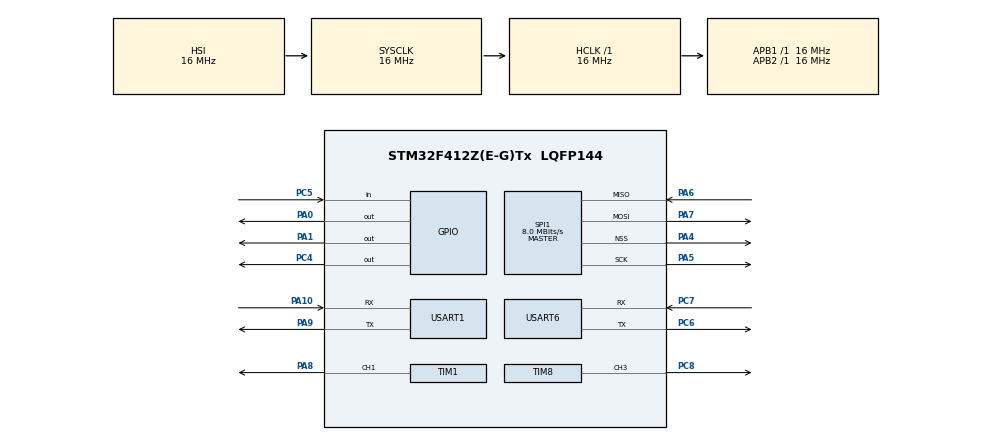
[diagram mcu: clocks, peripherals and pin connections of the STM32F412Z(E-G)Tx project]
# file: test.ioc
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Mcu.Family=STM32F4
Mcu.Name=STM32F412Z(E-G)Tx
Mcu.Package=LQFP144
NVIC.PriorityGroup=NVIC_PRIORITYGROUP_4
PA0.Signal=GPIO_Output
PA1.Signal=GPIO_Output
PA10.Mode=Asynchronous
PA10.Signal=USART1_RX
PA13.Mode=JTAG_5_pins
PA13.Signal=SYS_JTMS-SWDIO
PA14.Mode=JTAG_5_pins
PA14.Signal=SYS_JTCK-SWCLK
PA15.Mode=JTAG_5_pins
PA15.Signal=SYS_JTDI
PA4.Mode=NSS_Signal_Hard_Output
PA4.Signal=SPI1_NSS
PA5.Mode=Full_Duplex_Master
PA5.Signal=SPI1_SCK
PA6.Mode=Full_Duplex_Master
PA6.Signal=SPI1_MISO
PA7.Mode=Full_Duplex_Master
PA7.Signal=SPI1_MOSI
PA8.Signal=S_TIM1_CH1
PA9.Mode=Asynchronous
PA9.Signal=USART1_TX
PB3.Mode=JTAG_5_pins
PB3.Signal=SYS_JTDO-SWO
PB4.Mode=JTAG_5_pins
PB4.Signal=SYS_JTRST
PC4.Signal=GPIO_Output
PC5.Signal=GPIO_Input
PC6.Mode=Asynchronous
PC6.Signal=USART6_TX
PC7.Mode=Asynchronous
PC7.Signal=USART6_RX
PC8.Signal=S_TIM8_CH3
ProjectManager.HeapSize=0x200
ProjectManager.StackSize=0x400
ProjectManager.TargetToolchain=STM32CubeIDE
RCC.AHBFreq_Value=16000000
RCC.APB1Freq_Value=16000000
RCC.APB1TimFreq_Value=16000000
RCC.APB2Freq_Value=16000000
RCC.APB2TimFreq_Value=16000000
RCC.CortexFreq_Value=16000000
RCC.HCLKFreq_Value=16000000
RCC.SYSCLKFreq_VALUE=16000000
RCC.USBFreq_Value=96000000
RCC.VCOOutputFreq_Value=192000000
SH.S_TIM1_CH1.0=TIM1_CH1,PWM Generation1 CH1
SH.S_TIM8_CH3.0=TIM8_CH3,PWM Generation3 CH3
SPI1.CalculateBaudRate=8.0 MBits/s
SPI1.Direction=SPI_DIRECTION_2LINES
SPI1.Mode=SPI_MODE_MASTER
SPI1.VirtualNSS=VM_NSSHARD
SPI1.VirtualType=VM_MASTER
TIM1.Channel-PWM\ Generation1\ CH1=TIM_CHANNEL_1
TIM8.Channel-PWM\ Generation3\ CH3=TIM_CHANNEL_3
USART1.VirtualMode=VM_ASYNC
USART6.VirtualMode=VM_ASYNC
VP_TIM1_VS_ClockSourceINT.Mode=Internal
VP_TIM8_VS_ClockSourceINT.Mode=Internal
board=custom

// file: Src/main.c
/* USER CODE BEGIN Header */
/**
  ******************************************************************************
  * @file           : main.c
  * @brief          : Main program body
  ******************************************************************************
  * @attention
  *
  * <h2><center>&copy; Copyright (c) 2019 STMicroelectronics.
  * All rights reserved.</center></h2>
  *
  * This software component is licensed by ST under BSD 3-Clause license,
  * the "License"; You may not use this file except in compliance with the
  * License. You may obtain a copy of the License at:
  *                        opensource.org/licenses/BSD-3-Clause
  *
  ******************************************************************************
  */
/* USER CODE END Header */

#include "main.h"

SPI_HandleTypeDef hspi1;

TIM_HandleTypeDef htim1;
TIM_HandleTypeDef htim8;

UART_HandleTypeDef huart1;
UART_HandleTypeDef huart6;

void SystemClock_Config(void);
static void MX_GPIO_Init(void);
static void MX_SPI1_Init(void);
static void MX_TIM1_Init(void);
static void MX_TIM8_Init(void);
static void MX_USART1_UART_Init(void);
static void MX_USART6_UART_Init(void);
/* USER CODE BEGIN PFP */
static void FPGA_Programming(void);

/* USER CODE END PFP */

int main(void)
{

  /* MCU Configuration--------------------------------------------------------*/

  /* Reset of all peripherals, Initializes the Flash interface and the Systick. */
  HAL_Init();

  /* Configure the system clock */
  SystemClock_Config();

  /* Initialize all configured peripherals */
  MX_GPIO_Init();
  MX_SPI1_Init();
  MX_TIM1_Init();
  MX_TIM8_Init();
  MX_USART1_UART_Init();
  MX_USART6_UART_Init();
  /* USER CODE BEGIN 2 */
  FPGA_Programming();

  /* USER CODE END 2 */

  /* Infinite loop */
  while (1)
  {

  }
}

void SystemClock_Config(void)
{
  RCC_OscInitTypeDef RCC_OscInitStruct = {0};
  RCC_ClkInitTypeDef RCC_ClkInitStruct = {0};

  /** Configure the main internal regulator output voltage
  */
  __HAL_RCC_PWR_CLK_ENABLE();
  __HAL_PWR_VOLTAGESCALING_CONFIG(PWR_REGULATOR_VOLTAGE_SCALE1);
  /** Initializes the CPU, AHB and APB busses clocks
  */
  RCC_OscInitStruct.OscillatorType = RCC_OSCILLATORTYPE_HSI;
  RCC_OscInitStruct.HSIState = RCC_HSI_ON;
  RCC_OscInitStruct.HSICalibrationValue = RCC_HSICALIBRATION_DEFAULT;
  RCC_OscInitStruct.PLL.PLLState = RCC_PLL_NONE;
  if (HAL_RCC_OscConfig(&RCC_OscInitStruct) != HAL_OK)
  {
    Error_Handler();
  }
  /** Initializes the CPU, AHB and APB busses clocks
  */
  RCC_ClkInitStruct.ClockType = RCC_CLOCKTYPE_HCLK|RCC_CLOCKTYPE_SYSCLK
                              |RCC_CLOCKTYPE_PCLK1|RCC_CLOCKTYPE_PCLK2;
  RCC_ClkInitStruct.SYSCLKSource = RCC_SYSCLKSOURCE_HSI;
  RCC_ClkInitStruct.AHBCLKDivider = RCC_SYSCLK_DIV1;
  RCC_ClkInitStruct.APB1CLKDivider = RCC_HCLK_DIV1;
  RCC_ClkInitStruct.APB2CLKDivider = RCC_HCLK_DIV1;

  if (HAL_RCC_ClockConfig(&RCC_ClkInitStruct, FLASH_LATENCY_0) != HAL_OK)
  {
    Error_Handler();
  }
}

static void MX_SPI1_Init(void)
{

  /* SPI1 parameter configuration*/
  hspi1.Instance = SPI1;
  hspi1.Init.Mode = SPI_MODE_MASTER;
  hspi1.Init.Direction = SPI_DIRECTION_2LINES;
  hspi1.Init.DataSize = SPI_DATASIZE_8BIT;
  hspi1.Init.CLKPolarity = SPI_POLARITY_LOW;
  hspi1.Init.CLKPhase = SPI_PHASE_1EDGE;
  hspi1.Init.NSS = SPI_NSS_HARD_OUTPUT;
  hspi1.Init.BaudRatePrescaler = SPI_BAUDRATEPRESCALER_2;
  hspi1.Init.FirstBit = SPI_FIRSTBIT_MSB;
  hspi1.Init.TIMode = SPI_TIMODE_DISABLE;
  hspi1.Init.CRCCalculation = SPI_CRCCALCULATION_DISABLE;
  hspi1.Init.CRCPolynomial = 10;
  if (HAL_SPI_Init(&hspi1) != HAL_OK)
  {
    Error_Handler();
  }

}

static void MX_TIM1_Init(void)
{

  TIM_ClockConfigTypeDef sClockSourceConfig = {0};
  TIM_MasterConfigTypeDef sMasterConfig = {0};
  TIM_OC_InitTypeDef sConfigOC = {0};
  TIM_BreakDeadTimeConfigTypeDef sBreakDeadTimeConfig = {0};

  htim1.Instance = TIM1;
  htim1.Init.Prescaler = 0;
  htim1.Init.CounterMode = TIM_COUNTERMODE_UP;
  htim1.Init.Period = 0;
  htim1.Init.ClockDivision = TIM_CLOCKDIVISION_DIV1;
  htim1.Init.RepetitionCounter = 0;
  htim1.Init.AutoReloadPreload = TIM_AUTORELOAD_PRELOAD_DISABLE;
  if (HAL_TIM_Base_Init(&htim1) != HAL_OK)
  {
    Error_Handler();
  }
  sClockSourceConfig.ClockSource = TIM_CLOCKSOURCE_INTERNAL;
  if (HAL_TIM_ConfigClockSource(&htim1, &sClockSourceConfig) != HAL_OK)
  {
    Error_Handler();
  }
  if (HAL_TIM_PWM_Init(&htim1) != HAL_OK)
  {
    Error_Handler();
  }
  sMasterConfig.MasterOutputTrigger = TIM_TRGO_RESET;
  sMasterConfig.MasterSlaveMode = TIM_MASTERSLAVEMODE_DISABLE;
  if (HAL_TIMEx_MasterConfigSynchronization(&htim1, &sMasterConfig) != HAL_OK)
  {
    Error_Handler();
  }
  sConfigOC.OCMode = TIM_OCMODE_PWM1;
  sConfigOC.Pulse = 0;
  sConfigOC.OCPolarity = TIM_OCPOLARITY_HIGH;
  sConfigOC.OCNPolarity = TIM_OCNPOLARITY_HIGH;
  sConfigOC.OCFastMode = TIM_OCFAST_DISABLE;
  sConfigOC.OCIdleState = TIM_OCIDLESTATE_RESET;
  sConfigOC.OCNIdleState = TIM_OCNIDLESTATE_RESET;
  if (HAL_TIM_PWM_ConfigChannel(&htim1, &sConfigOC, TIM_CHANNEL_1) != HAL_OK)
  {
    Error_Handler();
  }
  sBreakDeadTimeConfig.OffStateRunMode = TIM_OSSR_DISABLE;
  sBreakDeadTimeConfig.OffStateIDLEMode = TIM_OSSI_DISABLE;
  sBreakDeadTimeConfig.LockLevel = TIM_LOCKLEVEL_OFF;
  sBreakDeadTimeConfig.DeadTime = 0;
  sBreakDeadTimeConfig.BreakState = TIM_BREAK_DISABLE;
  sBreakDeadTimeConfig.BreakPolarity = TIM_BREAKPOLARITY_HIGH;
  sBreakDeadTimeConfig.AutomaticOutput = TIM_AUTOMATICOUTPUT_DISABLE;
  if (HAL_TIMEx_ConfigBreakDeadTime(&htim1, &sBreakDeadTimeConfig) != HAL_OK)
  {
    Error_Handler();
  }
  HAL_TIM_MspPostInit(&htim1);

}

static void MX_TIM8_Init(void)
{

  TIM_ClockConfigTypeDef sClockSourceConfig = {0};
  TIM_MasterConfigTypeDef sMasterConfig = {0};
  TIM_OC_InitTypeDef sConfigOC = {0};
  TIM_BreakDeadTimeConfigTypeDef sBreakDeadTimeConfig = {0};

  htim8.Instance = TIM8;
  htim8.Init.Prescaler = 0;
  htim8.Init.CounterMode = TIM_COUNTERMODE_UP;
  htim8.Init.Period = 0;
  htim8.Init.ClockDivision = TIM_CLOCKDIVISION_DIV1;
  htim8.Init.RepetitionCounter = 0;
  htim8.Init.AutoReloadPreload = TIM_AUTORELOAD_PRELOAD_DISABLE;
  if (HAL_TIM_Base_Init(&htim8) != HAL_OK)
  {
    Error_Handler();
  }
  sClockSourceConfig.ClockSource = TIM_CLOCKSOURCE_INTERNAL;
  if (HAL_TIM_ConfigClockSource(&htim8, &sClockSourceConfig) != HAL_OK)
  {
    Error_Handler();
  }
  if (HAL_TIM_PWM_Init(&htim8) != HAL_OK)
  {
    Error_Handler();
  }
  sMasterConfig.MasterOutputTrigger = TIM_TRGO_RESET;
  sMasterConfig.MasterSlaveMode = TIM_MASTERSLAVEMODE_DISABLE;
  if (HAL_TIMEx_MasterConfigSynchronization(&htim8, &sMasterConfig) != HAL_OK)
  {
    Error_Handler();
  }
  sConfigOC.OCMode = TIM_OCMODE_PWM1;
  sConfigOC.Pulse = 0;
  sConfigOC.OCPolarity = TIM_OCPOLARITY_HIGH;
  sConfigOC.OCNPolarity = TIM_OCNPOLARITY_HIGH;
  sConfigOC.OCFastMode = TIM_OCFAST_DISABLE;
  sConfigOC.OCIdleState = TIM_OCIDLESTATE_RESET;
  sConfigOC.OCNIdleState = TIM_OCNIDLESTATE_RESET;
  if (HAL_TIM_PWM_ConfigChannel(&htim8, &sConfigOC, TIM_CHANNEL_3) != HAL_OK)
  {
    Error_Handler();
  }
  sBreakDeadTimeConfig.OffStateRunMode = TIM_OSSR_DISABLE;
  sBreakDeadTimeConfig.OffStateIDLEMode = TIM_OSSI_DISABLE;
  sBreakDeadTimeConfig.LockLevel = TIM_LOCKLEVEL_OFF;
  sBreakDeadTimeConfig.DeadTime = 0;
  sBreakDeadTimeConfig.BreakState = TIM_BREAK_DISABLE;
  sBreakDeadTimeConfig.BreakPolarity = TIM_BREAKPOLARITY_HIGH;
  sBreakDeadTimeConfig.AutomaticOutput = TIM_AUTOMATICOUTPUT_DISABLE;
  if (HAL_TIMEx_ConfigBreakDeadTime(&htim8, &sBreakDeadTimeConfig) != HAL_OK)
  {
    Error_Handler();
  }
  HAL_TIM_MspPostInit(&htim8);

}

static void MX_USART1_UART_Init(void)
{

  huart1.Instance = USART1;
  huart1.Init.BaudRate = 115200;
  huart1.Init.WordLength = UART_WORDLENGTH_8B;
  huart1.Init.StopBits = UART_STOPBITS_1;
  huart1.Init.Parity = UART_PARITY_NONE;
  huart1.Init.Mode = UART_MODE_TX_RX;
  huart1.Init.HwFlowCtl = UART_HWCONTROL_NONE;
  huart1.Init.OverSampling = UART_OVERSAMPLING_16;
  if (HAL_UART_Init(&huart1) != HAL_OK)
  {
    Error_Handler();
  }

}

static void MX_USART6_UART_Init(void)
{

  huart6.Instance = USART6;
  huart6.Init.BaudRate = 115200;
  huart6.Init.WordLength = UART_WORDLENGTH_8B;
  huart6.Init.StopBits = UART_STOPBITS_1;
  huart6.Init.Parity = UART_PARITY_NONE;
  huart6.Init.Mode = UART_MODE_TX_RX;
  huart6.Init.HwFlowCtl = UART_HWCONTROL_NONE;
  huart6.Init.OverSampling = UART_OVERSAMPLING_16;
  if (HAL_UART_Init(&huart6) != HAL_OK)
  {
    Error_Handler();
  }

}

static void MX_GPIO_Init(void)
{
  GPIO_InitTypeDef GPIO_InitStruct = {0};

  /* GPIO Ports Clock Enable */
  __HAL_RCC_GPIOE_CLK_ENABLE();
  __HAL_RCC_GPIOC_CLK_ENABLE();
  __HAL_RCC_GPIOF_CLK_ENABLE();
  __HAL_RCC_GPIOH_CLK_ENABLE();
  __HAL_RCC_GPIOA_CLK_ENABLE();
  __HAL_RCC_GPIOB_CLK_ENABLE();
  __HAL_RCC_GPIOG_CLK_ENABLE();
  __HAL_RCC_GPIOD_CLK_ENABLE();

  /*Configure GPIO pin Output Level */
  HAL_GPIO_WritePin(GPIOA, GPIO_PIN_0|GPIO_PIN_1, GPIO_PIN_RESET);

  /*Configure GPIO pin Output Level */
  HAL_GPIO_WritePin(GPIOC, GPIO_PIN_4, GPIO_PIN_RESET);

  /*Configure GPIO pins : PE2 PE3 PE4 PE5
                           PE6 PE7 PE8 PE9
                           PE10 PE11 PE12 PE13
                           PE14 PE15 PE0 PE1 */
  GPIO_InitStruct.Pin = GPIO_PIN_2|GPIO_PIN_3|GPIO_PIN_4|GPIO_PIN_5
                          |GPIO_PIN_6|GPIO_PIN_7|GPIO_PIN_8|GPIO_PIN_9
                          |GPIO_PIN_10|GPIO_PIN_11|GPIO_PIN_12|GPIO_PIN_13
                          |GPIO_PIN_14|GPIO_PIN_15|GPIO_PIN_0|GPIO_PIN_1;
  GPIO_InitStruct.Mode = GPIO_MODE_ANALOG;
  GPIO_InitStruct.Pull = GPIO_NOPULL;
  HAL_GPIO_Init(GPIOE, &GPIO_InitStruct);

  /*Configure GPIO pins : PC13 PC14 PC15 PC0
                           PC1 PC2 PC3 PC9
                           PC10 PC11 PC12 */
  GPIO_InitStruct.Pin = GPIO_PIN_13|GPIO_PIN_14|GPIO_PIN_15|GPIO_PIN_0
                          |GPIO_PIN_1|GPIO_PIN_2|GPIO_PIN_3|GPIO_PIN_9
                          |GPIO_PIN_10|GPIO_PIN_11|GPIO_PIN_12;
  GPIO_InitStruct.Mode = GPIO_MODE_ANALOG;
  GPIO_InitStruct.Pull = GPIO_NOPULL;
  HAL_GPIO_Init(GPIOC, &GPIO_InitStruct);

  /*Configure GPIO pins : PF0 PF1 PF2 PF3
                           PF4 PF5 PF6 PF7
                           PF8 PF9 PF10 PF11
                           PF12 PF13 PF14 PF15 */
  GPIO_InitStruct.Pin = GPIO_PIN_0|GPIO_PIN_1|GPIO_PIN_2|GPIO_PIN_3
                          |GPIO_PIN_4|GPIO_PIN_5|GPIO_PIN_6|GPIO_PIN_7
                          |GPIO_PIN_8|GPIO_PIN_9|GPIO_PIN_10|GPIO_PIN_11
                          |GPIO_PIN_12|GPIO_PIN_13|GPIO_PIN_14|GPIO_PIN_15;
  GPIO_InitStruct.Mode = GPIO_MODE_ANALOG;
  GPIO_InitStruct.Pull = GPIO_NOPULL;
  HAL_GPIO_Init(GPIOF, &GPIO_InitStruct);

  /*Configure GPIO pins : PH0 PH1 */
  GPIO_InitStruct.Pin = GPIO_PIN_0|GPIO_PIN_1;
  GPIO_InitStruct.Mode = GPIO_MODE_ANALOG;
  GPIO_InitStruct.Pull = GPIO_NOPULL;
  HAL_GPIO_Init(GPIOH, &GPIO_InitStruct);

  /*Configure GPIO pins : PA0 PA1 */
  GPIO_InitStruct.Pin = GPIO_PIN_0|GPIO_PIN_1;
  GPIO_InitStruct.Mode = GPIO_MODE_OUTPUT_PP;
  GPIO_InitStruct.Pull = GPIO_NOPULL;
  GPIO_InitStruct.Speed = GPIO_SPEED_FREQ_LOW;
  HAL_GPIO_Init(GPIOA, &GPIO_InitStruct);

  /*Configure GPIO pins : PA2 PA3 PA11 PA12 */
  GPIO_InitStruct.Pin = GPIO_PIN_2|GPIO_PIN_3|GPIO_PIN_11|GPIO_PIN_12;
  GPIO_InitStruct.Mode = GPIO_MODE_ANALOG;
  GPIO_InitStruct.Pull = GPIO_NOPULL;
  HAL_GPIO_Init(GPIOA, &GPIO_InitStruct);

  /*Configure GPIO pin : PC4 */
  GPIO_InitStruct.Pin = GPIO_PIN_4;
  GPIO_InitStruct.Mode = GPIO_MODE_OUTPUT_PP;
  GPIO_InitStruct.Pull = GPIO_NOPULL;
  GPIO_InitStruct.Speed = GPIO_SPEED_FREQ_LOW;
  HAL_GPIO_Init(GPIOC, &GPIO_InitStruct);

  /*Configure GPIO pin : PC5 */
  GPIO_InitStruct.Pin = GPIO_PIN_5;
  GPIO_InitStruct.Mode = GPIO_MODE_INPUT;
  GPIO_InitStruct.Pull = GPIO_NOPULL;
  HAL_GPIO_Init(GPIOC, &GPIO_InitStruct);

  /*Configure GPIO pins : PB0 PB1 PB2 PB10
                           PB11 PB12 PB13 PB14
                           PB15 PB5 PB6 PB7
                           PB8 PB9 */
  GPIO_InitStruct.Pin = GPIO_PIN_0|GPIO_PIN_1|GPIO_PIN_2|GPIO_PIN_10
                          |GPIO_PIN_11|GPIO_PIN_12|GPIO_PIN_13|GPIO_PIN_14
                          |GPIO_PIN_15|GPIO_PIN_5|GPIO_PIN_6|GPIO_PIN_7
                          |GPIO_PIN_8|GPIO_PIN_9;
  GPIO_InitStruct.Mode = GPIO_MODE_ANALOG;
  GPIO_InitStruct.Pull = GPIO_NOPULL;
  HAL_GPIO_Init(GPIOB, &GPIO_InitStruct);

  /*Configure GPIO pins : PG0 PG1 PG2 PG3
                           PG4 PG5 PG6 PG7
                           PG8 PG9 PG10 PG11
                           PG12 PG13 PG14 PG15 */
  GPIO_InitStruct.Pin = GPIO_PIN_0|GPIO_PIN_1|GPIO_PIN_2|GPIO_PIN_3
                          |GPIO_PIN_4|GPIO_PIN_5|GPIO_PIN_6|GPIO_PIN_7
                          |GPIO_PIN_8|GPIO_PIN_9|GPIO_PIN_10|GPIO_PIN_11
                          |GPIO_PIN_12|GPIO_PIN_13|GPIO_PIN_14|GPIO_PIN_15;
  GPIO_InitStruct.Mode = GPIO_MODE_ANALOG;
  GPIO_InitStruct.Pull = GPIO_NOPULL;
  HAL_GPIO_Init(GPIOG, &GPIO_InitStruct);

  /*Configure GPIO pins : PD8 PD9 PD10 PD11
                           PD12 PD13 PD14 PD15
                           PD0 PD1 PD2 PD3
                           PD4 PD5 PD6 PD7 */
  GPIO_InitStruct.Pin = GPIO_PIN_8|GPIO_PIN_9|GPIO_PIN_10|GPIO_PIN_11
                          |GPIO_PIN_12|GPIO_PIN_13|GPIO_PIN_14|GPIO_PIN_15
                          |GPIO_PIN_0|GPIO_PIN_1|GPIO_PIN_2|GPIO_PIN_3
                          |GPIO_PIN_4|GPIO_PIN_5|GPIO_PIN_6|GPIO_PIN_7;
  GPIO_InitStruct.Mode = GPIO_MODE_ANALOG;
  GPIO_InitStruct.Pull = GPIO_NOPULL;
  HAL_GPIO_Init(GPIOD, &GPIO_InitStruct);

}

/* USER CODE BEGIN 4 */

/* Function to program FPGA on board
 * This function must be run every time because FPGA does not hold its programming
 */
static void FPGA_Programming(void){

}

/* USER CODE END 4 */

void Error_Handler(void)
{
}

/************************ (C) COPYRIGHT STMicroelectronics *****END OF FILE****/
